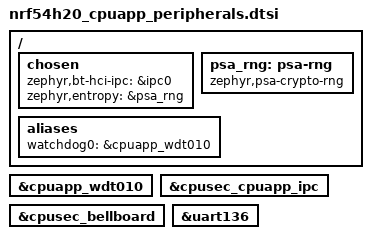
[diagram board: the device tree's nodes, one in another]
/*
 * Copyright (c) 2024 Nordic Semiconductor ASA
 *
 * SPDX-License-Identifier: LicenseRef-Nordic-5-Clause
 */

/*
 * This file contains all peripherals needed by the Application core for Matter purposes
 */

/ {
	chosen {
		/* prepare IPC to HCI Radio core */
		zephyr,bt-hci-ipc = &ipc0;
		zephyr,entropy = &psa_rng;
	};

	psa_rng: psa-rng {
		compatible = "zephyr,psa-crypto-rng";
		status = "okay";
	};

	aliases {
		watchdog0 = &cpuapp_wdt010;
	};
};

/* Watchdog */
&cpuapp_wdt010 {
	status = "okay";
};

/* Communication between Application Core and Secure domain for SUIT */
&cpusec_cpuapp_ipc {
	status = "okay";
};
&cpusec_bellboard {
	status = "okay";
};

/* Disable HW flow control for UART */
&uart136 {
	/delete-property/ hw-flow-control;
};
